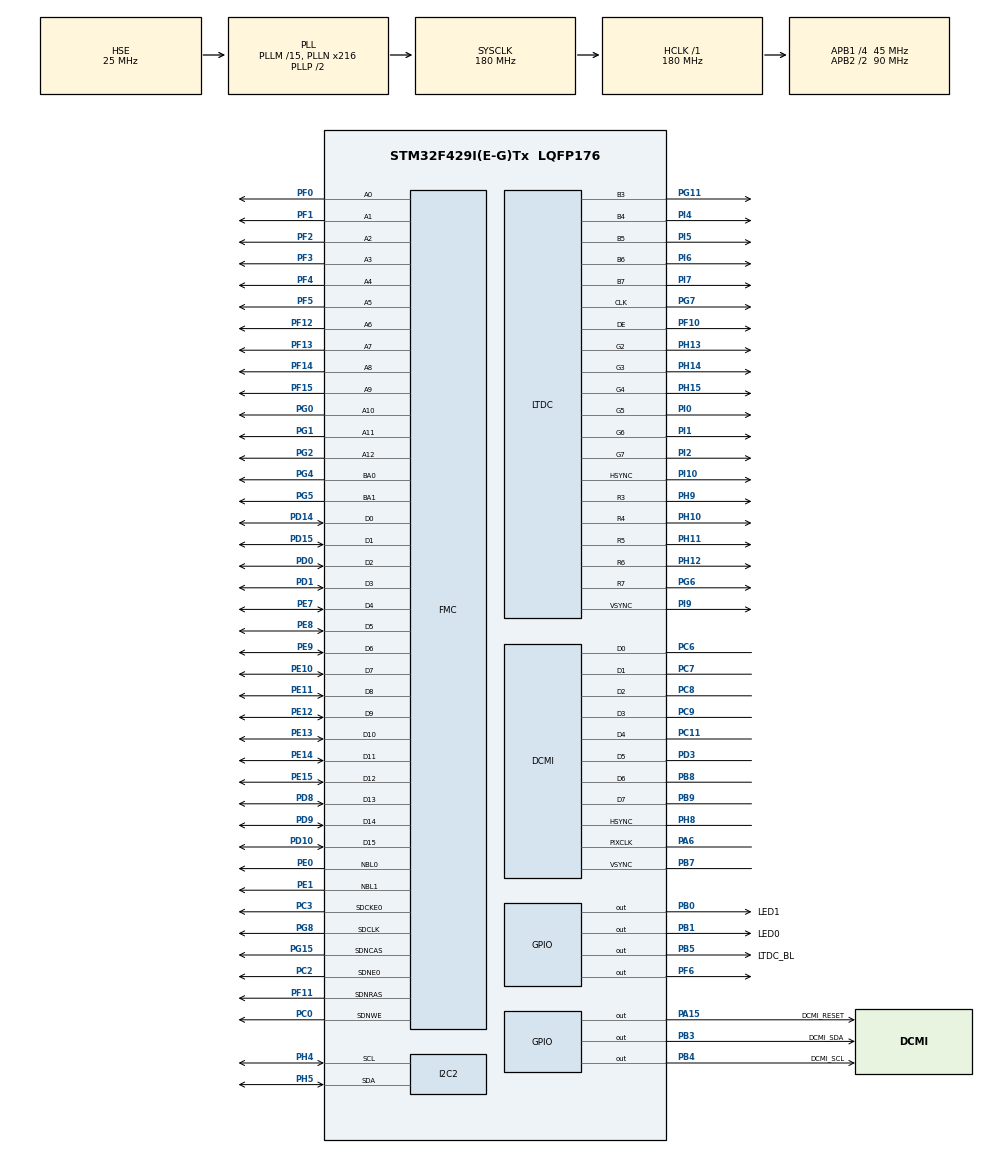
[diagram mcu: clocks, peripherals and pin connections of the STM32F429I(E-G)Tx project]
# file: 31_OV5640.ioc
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DCMI.PCKPolarity=DCMI_PCKPOLARITY_RISING
DMA2D.AlphaModeForeground=DMA2D_NO_MODIF_ALPHA
DMA2D.ColorMode=DMA2D_OUTPUT_RGB565
DMA2D.InputAlphaForeground=0
DMA2D.Mode=DMA2D_M2M
Dma.DCMI.0.Direction=DMA_PERIPH_TO_MEMORY
Dma.DCMI.0.FIFOMode=DMA_FIFOMODE_ENABLE
Dma.DCMI.0.FIFOThreshold=DMA_FIFO_THRESHOLD_HALFFULL
Dma.DCMI.0.Instance=DMA2_Stream1
Dma.DCMI.0.MemBurst=DMA_MBURST_SINGLE
Dma.DCMI.0.MemDataAlignment=DMA_MDATAALIGN_HALFWORD
Dma.DCMI.0.MemInc=DMA_MINC_ENABLE
Dma.DCMI.0.Mode=DMA_CIRCULAR
Dma.DCMI.0.PeriphBurst=DMA_PBURST_SINGLE
Dma.DCMI.0.PeriphDataAlignment=DMA_PDATAALIGN_WORD
Dma.DCMI.0.PeriphInc=DMA_PINC_DISABLE
Dma.DCMI.0.Priority=DMA_PRIORITY_HIGH
Dma.Request0=DCMI
FMC.CASLatency1=FMC_SDRAM_CAS_LATENCY_3
FMC.ColumnBitsNumber1=FMC_SDRAM_COLUMN_BITS_NUM_9
FMC.ExitSelfRefreshDelay1=7
FMC.LoadToActiveDelay1=2
FMC.RCDDelay1=2
FMC.RPDelay1=2
FMC.RPDelay2=2
FMC.ReadBurst1=FMC_SDRAM_RBURST_ENABLE
FMC.ReadBurst2=FMC_SDRAM_RBURST_ENABLE
FMC.ReadPipeDelay1=FMC_SDRAM_RPIPE_DELAY_1
FMC.ReadPipeDelay2=FMC_SDRAM_RPIPE_DELAY_1
FMC.RowCycleDelay1=6
FMC.RowCycleDelay2=6
FMC.SDClockPeriod1=FMC_SDRAM_CLOCK_PERIOD_2
FMC.SDClockPeriod2=FMC_SDRAM_CLOCK_PERIOD_2
FMC.SelfRefreshTime1=4
FMC.WriteRecoveryTime1=2
LTDC.ActiveH=600
LTDC.ActiveW=1024
LTDC.Alpha0_L1=255
LTDC.Alpha_L0=255
LTDC.Alpha_L1=0
LTDC.FBStartAdress_L0=0xC0000000
LTDC.FBStartAdress_L1=0xC0400000
LTDC.Green_L1=0
LTDC.HBP=140
LTDC.HFP=160
LTDC.HSync=20
LTDC.ImageHeight_L0=120
LTDC.ImageHeight_L1=120
LTDC.ImageWidth_L0=160
LTDC.ImageWidth_L1=160
LTDC.Layers=0
LTDC.PixelFormat_L0=LTDC_PIXEL_FORMAT_RGB565
LTDC.PixelFormat_L1=LTDC_PIXEL_FORMAT_RGB565
LTDC.VBP=20
LTDC.VFP=12
LTDC.VSync=3
LTDC.WindowX0_L1=200
LTDC.WindowX1_L0=159
LTDC.WindowX1_L1=359
LTDC.WindowY0_L1=200
LTDC.WindowY1_L0=119
LTDC.WindowY1_L1=319
Mcu.Family=STM32F4
Mcu.Name=STM32F429I(E-G)Tx
Mcu.Package=LQFP176
NVIC.DCMI_IRQn=true\:0\:1\:true\:false\:true\:true\:true
NVIC.DMA2_Stream1_IRQn=true\:0\:0\:false\:true\:true\:1\:false\:true
NVIC.PriorityGroup=NVIC_PRIORITYGROUP_2
PA13.Mode=Serial_Wire
PA13.Signal=SYS_JTMS-SWDIO
PA14.Mode=Serial_Wire
PA14.Signal=SYS_JTCK-SWCLK
PA15.GPIO_Label=DCMI_RESET
PA15.Signal=GPIO_Output
PA6.GPIO_PuPd=GPIO_PULLUP
PA6.GPIO_Speed=GPIO_SPEED_FREQ_VERY_HIGH
PA6.Mode=Slave_8_bits_External_Synchro
PA6.Signal=DCMI_PIXCLK
PB0.GPIO_Label=LED1
PB0.PinState=GPIO_PIN_SET
PB0.Signal=GPIO_Output
PB1.GPIO_Label=LED0
PB1.GPIO_PuPd=GPIO_PULLUP
PB1.PinState=GPIO_PIN_SET
PB1.Signal=GPIO_Output
PB3.GPIO_Label=DCMI_SDA
PB3.GPIO_ModeDefaultOutputPP=GPIO_MODE_OUTPUT_PP
PB3.GPIO_PuPd=GPIO_PULLUP
PB3.GPIO_Speed=GPIO_SPEED_FREQ_VERY_HIGH
PB3.Signal=GPIO_Output
PB4.GPIO_Label=DCMI_SCL
PB4.GPIO_ModeDefaultOutputPP=GPIO_MODE_OUTPUT_PP
PB4.GPIO_PuPd=GPIO_PULLUP
PB4.GPIO_Speed=GPIO_SPEED_FREQ_VERY_HIGH
PB4.Signal=GPIO_Output
PB5.GPIO_Label=LTDC_BL
PB5.Signal=GPIO_Output
PB7.GPIO_PuPd=GPIO_PULLUP
PB7.GPIO_Speed=GPIO_SPEED_FREQ_VERY_HIGH
PB7.Mode=Slave_8_bits_External_Synchro
PB7.Signal=DCMI_VSYNC
PB8.GPIO_PuPd=GPIO_PULLUP
PB8.GPIO_Speed=GPIO_SPEED_FREQ_VERY_HIGH
PB8.Mode=Slave_8_bits_External_Synchro
PB8.Signal=DCMI_D6
PB9.GPIO_PuPd=GPIO_PULLUP
PB9.GPIO_Speed=GPIO_SPEED_FREQ_VERY_HIGH
PB9.Mode=Slave_8_bits_External_Synchro
PB9.Signal=DCMI_D7
PC0.GPIO_Mode=GPIO_MODE_AF_PP
PC0.GPIO_PuPd=GPIO_PULLUP
PC0.GPIO_Speed_High_Default=GPIO_SPEED_FREQ_VERY_HIGH
PC0.Signal=FMC_SDNWE
PC11.GPIO_PuPd=GPIO_PULLUP
PC11.GPIO_Speed=GPIO_SPEED_FREQ_VERY_HIGH
PC11.Mode=Slave_8_bits_External_Synchro
PC11.Signal=DCMI_D4
PC14/OSC32_IN.Mode=LSE-External-Oscillator
PC14/OSC32_IN.Signal=RCC_OSC32_IN
PC15/OSC32_OUT.Mode=LSE-External-Oscillator
PC15/OSC32_OUT.Signal=RCC_OSC32_OUT
PC2.GPIO_Mode=GPIO_MODE_AF_PP
PC2.GPIO_PuPd=GPIO_PULLUP
PC2.GPIO_Speed_High_Default=GPIO_SPEED_FREQ_VERY_HIGH
PC2.Mode=SdramChipSelect1_1
PC2.Signal=FMC_SDNE0
PC3.GPIO_Mode=GPIO_MODE_AF_PP
PC3.GPIO_PuPd=GPIO_PULLUP
PC3.GPIO_Speed_High_Default=GPIO_SPEED_FREQ_VERY_HIGH
PC3.Mode=SdramChipSelect1_1
PC3.Signal=FMC_SDCKE0
PC6.GPIO_PuPd=GPIO_PULLUP
PC6.GPIO_Speed=GPIO_SPEED_FREQ_VERY_HIGH
PC6.Mode=Slave_8_bits_External_Synchro
PC6.Signal=DCMI_D0
PC7.GPIO_PuPd=GPIO_PULLUP
PC7.GPIO_Speed=GPIO_SPEED_FREQ_VERY_HIGH
PC7.Mode=Slave_8_bits_External_Synchro
PC7.Signal=DCMI_D1
PC8.GPIO_PuPd=GPIO_PULLUP
PC8.GPIO_Speed=GPIO_SPEED_FREQ_VERY_HIGH
PC8.Mode=Slave_8_bits_External_Synchro
PC8.Signal=DCMI_D2
PC9.GPIO_PuPd=GPIO_PULLUP
PC9.GPIO_Speed=GPIO_SPEED_FREQ_VERY_HIGH
PC9.Mode=Slave_8_bits_External_Synchro
PC9.Signal=DCMI_D3
PD0.GPIO_Mode=GPIO_MODE_AF_PP
PD0.GPIO_PuPd=GPIO_PULLUP
PD0.GPIO_Speed_High_Default=GPIO_SPEED_FREQ_VERY_HIGH
PD0.Signal=FMC_D2_DA2
PD1.GPIO_Mode=GPIO_MODE_AF_PP
PD1.GPIO_PuPd=GPIO_PULLUP
PD1.GPIO_Speed_High_Default=GPIO_SPEED_FREQ_VERY_HIGH
PD1.Signal=FMC_D3_DA3
PD10.GPIO_Mode=GPIO_MODE_AF_PP
PD10.GPIO_PuPd=GPIO_PULLUP
PD10.GPIO_Speed_High_Default=GPIO_SPEED_FREQ_VERY_HIGH
PD10.Signal=FMC_D15_DA15
PD14.GPIO_Mode=GPIO_MODE_AF_PP
PD14.GPIO_PuPd=GPIO_PULLUP
PD14.GPIO_Speed_High_Default=GPIO_SPEED_FREQ_VERY_HIGH
PD14.Signal=FMC_D0_DA0
PD15.GPIO_Mode=GPIO_MODE_AF_PP
PD15.GPIO_PuPd=GPIO_PULLUP
PD15.GPIO_Speed_High_Default=GPIO_SPEED_FREQ_VERY_HIGH
PD15.Signal=FMC_D1_DA1
PD3.GPIO_PuPd=GPIO_PULLUP
PD3.GPIO_Speed=GPIO_SPEED_FREQ_VERY_HIGH
PD3.Mode=Slave_8_bits_External_Synchro
PD3.Signal=DCMI_D5
PD8.GPIO_Mode=GPIO_MODE_AF_PP
PD8.GPIO_PuPd=GPIO_PULLUP
PD8.GPIO_Speed_High_Default=GPIO_SPEED_FREQ_VERY_HIGH
PD8.Signal=FMC_D13_DA13
PD9.GPIO_Mode=GPIO_MODE_AF_PP
PD9.GPIO_PuPd=GPIO_PULLUP
PD9.GPIO_Speed_High_Default=GPIO_SPEED_FREQ_VERY_HIGH
PD9.Signal=FMC_D14_DA14
PE0.GPIO_Mode=GPIO_MODE_AF_PP
PE0.GPIO_PuPd=GPIO_PULLUP
PE0.GPIO_Speed_High_Default=GPIO_SPEED_FREQ_VERY_HIGH
PE0.Signal=FMC_NBL0
PE1.GPIO_Mode=GPIO_MODE_AF_PP
PE1.GPIO_PuPd=GPIO_PULLUP
PE1.GPIO_Speed_High_Default=GPIO_SPEED_FREQ_VERY_HIGH
PE1.Signal=FMC_NBL1
PE10.GPIO_Mode=GPIO_MODE_AF_PP
PE10.GPIO_PuPd=GPIO_PULLUP
PE10.GPIO_Speed_High_Default=GPIO_SPEED_FREQ_VERY_HIGH
PE10.Signal=FMC_D7_DA7
PE11.GPIO_Mode=GPIO_MODE_AF_PP
PE11.GPIO_PuPd=GPIO_PULLUP
PE11.GPIO_Speed_High_Default=GPIO_SPEED_FREQ_VERY_HIGH
PE11.Signal=FMC_D8_DA8
PE12.GPIO_Mode=GPIO_MODE_AF_PP
PE12.GPIO_PuPd=GPIO_PULLUP
PE12.GPIO_Speed_High_Default=GPIO_SPEED_FREQ_VERY_HIGH
PE12.Signal=FMC_D9_DA9
PE13.GPIO_Mode=GPIO_MODE_AF_PP
PE13.GPIO_PuPd=GPIO_PULLUP
PE13.GPIO_Speed_High_Default=GPIO_SPEED_FREQ_VERY_HIGH
PE13.Signal=FMC_D10_DA10
PE14.GPIO_Mode=GPIO_MODE_AF_PP
PE14.GPIO_PuPd=GPIO_PULLUP
PE14.GPIO_Speed_High_Default=GPIO_SPEED_FREQ_VERY_HIGH
PE14.Signal=FMC_D11_DA11
PE15.GPIO_Mode=GPIO_MODE_AF_PP
PE15.GPIO_PuPd=GPIO_PULLUP
PE15.GPIO_Speed_High_Default=GPIO_SPEED_FREQ_VERY_HIGH
PE15.Signal=FMC_D12_DA12
PE7.GPIO_Mode=GPIO_MODE_AF_PP
PE7.GPIO_PuPd=GPIO_PULLUP
PE7.GPIO_Speed_High_Default=GPIO_SPEED_FREQ_VERY_HIGH
PE7.Signal=FMC_D4_DA4
PE8.GPIO_Mode=GPIO_MODE_AF_PP
PE8.GPIO_PuPd=GPIO_PULLUP
PE8.GPIO_Speed_High_Default=GPIO_SPEED_FREQ_VERY_HIGH
PE8.Signal=FMC_D5_DA5
PE9.GPIO_Mode=GPIO_MODE_AF_PP
PE9.GPIO_PuPd=GPIO_PULLUP
PE9.GPIO_Speed_High_Default=GPIO_SPEED_FREQ_VERY_HIGH
PE9.Signal=FMC_D6_DA6
PF0.GPIO_Mode=GPIO_MODE_AF_PP
PF0.GPIO_PuPd=GPIO_PULLUP
PF0.GPIO_Speed_High_Default=GPIO_SPEED_FREQ_VERY_HIGH
PF0.Signal=FMC_A0
PF1.GPIO_Mode=GPIO_MODE_AF_PP
PF1.GPIO_PuPd=GPIO_PULLUP
PF1.GPIO_Speed_High_Default=GPIO_SPEED_FREQ_VERY_HIGH
PF1.Signal=FMC_A1
PF10.GPIO_Speed=GPIO_SPEED_FREQ_VERY_HIGH
PF10.Mode=RGB565
PF10.Signal=LTDC_DE
PF11.GPIO_Mode=GPIO_MODE_AF_PP
PF11.GPIO_PuPd=GPIO_PULLUP
PF11.GPIO_Speed_High_Default=GPIO_SPEED_FREQ_VERY_HIGH
PF11.Signal=FMC_SDNRAS
PF12.GPIO_Mode=GPIO_MODE_AF_PP
PF12.GPIO_PuPd=GPIO_PULLUP
PF12.GPIO_Speed_High_Default=GPIO_SPEED_FREQ_VERY_HIGH
PF12.Signal=FMC_A6
PF13.GPIO_Mode=GPIO_MODE_AF_PP
PF13.GPIO_PuPd=GPIO_PULLUP
PF13.GPIO_Speed_High_Default=GPIO_SPEED_FREQ_VERY_HIGH
PF13.Signal=FMC_A7
PF14.GPIO_Mode=GPIO_MODE_AF_PP
PF14.GPIO_PuPd=GPIO_PULLUP
PF14.GPIO_Speed_High_Default=GPIO_SPEED_FREQ_VERY_HIGH
PF14.Signal=FMC_A8
PF15.GPIO_Mode=GPIO_MODE_AF_PP
PF15.GPIO_PuPd=GPIO_PULLUP
PF15.GPIO_Speed_High_Default=GPIO_SPEED_FREQ_VERY_HIGH
PF15.Signal=FMC_A9
PF2.GPIO_Mode=GPIO_MODE_AF_PP
PF2.GPIO_PuPd=GPIO_PULLUP
PF2.GPIO_Speed_High_Default=GPIO_SPEED_FREQ_VERY_HIGH
PF2.Signal=FMC_A2
PF3.GPIO_Mode=GPIO_MODE_AF_PP
PF3.GPIO_PuPd=GPIO_PULLUP
PF3.GPIO_Speed_High_Default=GPIO_SPEED_FREQ_VERY_HIGH
PF3.Signal=FMC_A3
PF4.GPIO_Mode=GPIO_MODE_AF_PP
PF4.GPIO_PuPd=GPIO_PULLUP
PF4.GPIO_Speed_High_Default=GPIO_SPEED_FREQ_VERY_HIGH
PF4.Signal=FMC_A4
PF5.GPIO_Mode=GPIO_MODE_AF_PP
PF5.GPIO_PuPd=GPIO_PULLUP
PF5.GPIO_Speed_High_Default=GPIO_SPEED_FREQ_VERY_HIGH
PF5.Signal=FMC_A5
PF6.GPIO_Speed=GPIO_SPEED_FREQ_VERY_HIGH
PF6.Signal=GPIO_Output
PG0.GPIO_Mode=GPIO_MODE_AF_PP
PG0.GPIO_PuPd=GPIO_PULLUP
PG0.GPIO_Speed_High_Default=GPIO_SPEED_FREQ_VERY_HIGH
PG0.Signal=FMC_A10
PG1.GPIO_Mode=GPIO_MODE_AF_PP
PG1.GPIO_PuPd=GPIO_PULLUP
PG1.GPIO_Speed_High_Default=GPIO_SPEED_FREQ_VERY_HIGH
PG1.Signal=FMC_A11
PG11.GPIO_Speed=GPIO_SPEED_FREQ_VERY_HIGH
PG11.Mode=RGB565
PG11.Signal=LTDC_B3
PG15.GPIO_Mode=GPIO_MODE_AF_PP
PG15.GPIO_PuPd=GPIO_PULLUP
PG15.GPIO_Speed_High_Default=GPIO_SPEED_FREQ_VERY_HIGH
PG15.Signal=FMC_SDNCAS
PG2.GPIO_Mode=GPIO_MODE_AF_PP
PG2.GPIO_PuPd=GPIO_PULLUP
PG2.GPIO_Speed_High_Default=GPIO_SPEED_FREQ_VERY_HIGH
PG2.Signal=FMC_A12
PG4.GPIO_Mode=GPIO_MODE_AF_PP
PG4.GPIO_PuPd=GPIO_PULLUP
PG4.GPIO_Speed_High_Default=GPIO_SPEED_FREQ_VERY_HIGH
PG4.Signal=FMC_A14_BA0
PG5.GPIO_Mode=GPIO_MODE_AF_PP
PG5.GPIO_PuPd=GPIO_PULLUP
PG5.GPIO_Speed_High_Default=GPIO_SPEED_FREQ_VERY_HIGH
PG5.Signal=FMC_A15_BA1
PG6.GPIO_Speed=GPIO_SPEED_FREQ_VERY_HIGH
PG6.Mode=RGB565
PG6.Signal=LTDC_R7
PG7.GPIO_Speed=GPIO_SPEED_FREQ_VERY_HIGH
PG7.Mode=RGB565
PG7.Signal=LTDC_CLK
PG8.GPIO_Mode=GPIO_MODE_AF_PP
PG8.GPIO_PuPd=GPIO_PULLUP
PG8.GPIO_Speed_High_Default=GPIO_SPEED_FREQ_VERY_HIGH
PG8.Signal=FMC_SDCLK
PH0/OSC_IN.Mode=HSE-External-Oscillator
PH0/OSC_IN.Signal=RCC_OSC_IN
PH1/OSC_OUT.Mode=HSE-External-Oscillator
PH1/OSC_OUT.Signal=RCC_OSC_OUT
PH10.GPIO_Speed=GPIO_SPEED_FREQ_VERY_HIGH
PH10.Mode=RGB565
PH10.Signal=LTDC_R4
PH11.GPIO_Speed=GPIO_SPEED_FREQ_VERY_HIGH
PH11.Mode=RGB565
PH11.Signal=LTDC_R5
PH12.GPIO_Speed=GPIO_SPEED_FREQ_VERY_HIGH
PH12.Mode=RGB565
PH12.Signal=LTDC_R6
PH13.GPIO_Speed=GPIO_SPEED_FREQ_VERY_HIGH
PH13.Mode=RGB565
PH13.Signal=LTDC_G2
PH14.GPIO_Speed=GPIO_SPEED_FREQ_VERY_HIGH
PH14.Mode=RGB565
PH14.Signal=LTDC_G3
PH15.GPIO_Speed=GPIO_SPEED_FREQ_VERY_HIGH
PH15.Mode=RGB565
PH15.Signal=LTDC_G4
PH4.Mode=I2C
PH4.Signal=I2C2_SCL
PH5.Mode=I2C
PH5.Signal=I2C2_SDA
PH8.GPIO_PuPd=GPIO_PULLUP
PH8.GPIO_Speed=GPIO_SPEED_FREQ_VERY_HIGH
PH8.Mode=Slave_8_bits_External_Synchro
PH8.Signal=DCMI_HSYNC
PH9.GPIO_Speed=GPIO_SPEED_FREQ_VERY_HIGH
PH9.Mode=RGB565
PH9.Signal=LTDC_R3
PI0.GPIO_Speed=GPIO_SPEED_FREQ_VERY_HIGH
PI0.Mode=RGB565
PI0.Signal=LTDC_G5
PI1.GPIO_Speed=GPIO_SPEED_FREQ_VERY_HIGH
PI1.Mode=RGB565
PI1.Signal=LTDC_G6
PI10.GPIO_Speed=GPIO_SPEED_FREQ_VERY_HIGH
PI10.Mode=RGB565
PI10.Signal=LTDC_HSYNC
PI2.GPIO_Speed=GPIO_SPEED_FREQ_VERY_HIGH
PI2.Mode=RGB565
PI2.Signal=LTDC_G7
PI4.GPIO_Speed=GPIO_SPEED_FREQ_VERY_HIGH
PI4.Mode=RGB565
PI4.Signal=LTDC_B4
PI5.GPIO_Speed=GPIO_SPEED_FREQ_VERY_HIGH
PI5.Mode=RGB565
PI5.Signal=LTDC_B5
PI6.GPIO_Speed=GPIO_SPEED_FREQ_VERY_HIGH
PI6.Mode=RGB565
PI6.Signal=LTDC_B6
PI7.GPIO_Speed=GPIO_SPEED_FREQ_VERY_HIGH
PI7.Mode=RGB565
PI7.Signal=LTDC_B7
PI9.GPIO_Speed=GPIO_SPEED_FREQ_VERY_HIGH
PI9.Mode=RGB565
PI9.Signal=LTDC_VSYNC
ProjectManager.HeapSize=0x200
ProjectManager.StackSize=0x400
ProjectManager.TargetToolchain=STM32CubeIDE
RCC.48MHZClocksFreq_Value=90000000
RCC.AHBFreq_Value=180000000
RCC.APB1CLKDivider=RCC_HCLK_DIV4
RCC.APB1Freq_Value=45000000
RCC.APB1TimFreq_Value=90000000
RCC.APB2CLKDivider=RCC_HCLK_DIV2
RCC.APB2Freq_Value=90000000
RCC.APB2TimFreq_Value=180000000
RCC.CortexFreq_Value=180000000
RCC.HCLKFreq_Value=180000000
RCC.HSE_VALUE=25000000
RCC.HSI_VALUE=16000000
RCC.PLLM=15
RCC.PLLN=216
RCC.PLLSAIN=168
RCC.PLLSAIR=5
RCC.PLLSourceVirtual=RCC_PLLSOURCE_HSE
RCC.SYSCLKFreq_VALUE=180000000
RCC.SYSCLKSource=RCC_SYSCLKSOURCE_PLLCLK
RCC.VCOOutputFreq_Value=360000000
SH.FMC_A0.0=FMC_A0,13b-sda1
SH.FMC_A1.0=FMC_A1,13b-sda1
SH.FMC_A10.0=FMC_A10,13b-sda1
SH.FMC_A11.0=FMC_A11,13b-sda1
SH.FMC_A12.0=FMC_A12,13b-sda1
SH.FMC_A14_BA0.0=FMC_BA0,FourSdramBanks1
SH.FMC_A15_BA1.0=FMC_BA1,FourSdramBanks1
SH.FMC_A2.0=FMC_A2,13b-sda1
SH.FMC_A3.0=FMC_A3,13b-sda1
SH.FMC_A4.0=FMC_A4,13b-sda1
SH.FMC_A5.0=FMC_A5,13b-sda1
SH.FMC_A6.0=FMC_A6,13b-sda1
SH.FMC_A7.0=FMC_A7,13b-sda1
SH.FMC_A8.0=FMC_A8,13b-sda1
SH.FMC_A9.0=FMC_A9,13b-sda1
SH.FMC_D0_DA0.0=FMC_D0,sd-16b-d1
SH.FMC_D10_DA10.0=FMC_D10,sd-16b-d1
SH.FMC_D11_DA11.0=FMC_D11,sd-16b-d1
SH.FMC_D12_DA12.0=FMC_D12,sd-16b-d1
SH.FMC_D13_DA13.0=FMC_D13,sd-16b-d1
SH.FMC_D14_DA14.0=FMC_D14,sd-16b-d1
SH.FMC_D15_DA15.0=FMC_D15,sd-16b-d1
SH.FMC_D1_DA1.0=FMC_D1,sd-16b-d1
SH.FMC_D2_DA2.0=FMC_D2,sd-16b-d1
SH.FMC_D3_DA3.0=FMC_D3,sd-16b-d1
SH.FMC_D4_DA4.0=FMC_D4,sd-16b-d1
SH.FMC_D5_DA5.0=FMC_D5,sd-16b-d1
SH.FMC_D6_DA6.0=FMC_D6,sd-16b-d1
SH.FMC_D7_DA7.0=FMC_D7,sd-16b-d1
SH.FMC_D8_DA8.0=FMC_D8,sd-16b-d1
SH.FMC_D9_DA9.0=FMC_D9,sd-16b-d1
SH.FMC_NBL0.0=FMC_NBL0,Sd2ByteEnable1
SH.FMC_NBL1.0=FMC_NBL1,Sd2ByteEnable1
SH.FMC_SDCLK.0=FMC_SDCLK,13b-sda1
SH.FMC_SDNCAS.0=FMC_SDNCAS,13b-sda1
SH.FMC_SDNRAS.0=FMC_SDNRAS,13b-sda1
SH.FMC_SDNWE.0=FMC_SDNWE,13b-sda1
VP_DMA2D_VS_DMA2D.Mode=DMA2D_Activate
board=custom

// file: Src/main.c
/* USER CODE BEGIN Header */
/**
 ******************************************************************************
 * @file           : main.c
 * @brief          : Main program body
 ******************************************************************************
 * @attention
 *
 * <h2><center>&copy; Copyright (c) 2019 STMicroelectronics.
 * All rights reserved.</center></h2>
 *
 * This software component is licensed by ST under BSD 3-Clause license,
 * the "License"; You may not use this file except in compliance with the
 * License. You may obtain a copy of the License at:
 *                        opensource.org/licenses/BSD-3-Clause
 *
 ******************************************************************************
 */
/* USER CODE END Header */

#include "main.h"
#include "dcmi.h"
#include "dma.h"
#include "dma2d.h"
#include "i2c.h"
#include "ltdc.h"
#include "gpio.h"
#include "fmc.h"

/* USER CODE BEGIN Includes */
#include "LTDC_LCD.h"
#include "sdRAM.h"
#include "OV5640.h"
//#include "RGB565_240x130_1.h"
//#include "RGB565_320x240.h"
//#include"test_pic3.h"
/* USER CODE END Includes */

/* USER CODE BEGIN PD */
#define SDRAM_BANK_ADDR     ((uint32_t)0XC0000000)
#define jpeg_buf_size   30*1024*1024		//定义JPEG数据缓存jpeg_buf的大�???????????????????????(1*4M字节)
#define jpeg_line_size	2*1024			//定义DMA接收数据�???????????????????????,�???????????????????????行数据的�???????????????????????大�??

typedef int32_t s32;
typedef int16_t s16;
typedef int8_t s8;

typedef const int32_t sc32;
typedef const int16_t sc16;
typedef const int8_t sc8;

typedef __IO int32_t vs32;
typedef __IO int16_t vs16;
typedef __IO int8_t vs8;

typedef __I int32_t vsc32;
typedef __I int16_t vsc16;
typedef __I int8_t vsc8;

typedef uint32_t u32;
typedef uint16_t u16;
typedef uint8_t u8;

typedef const uint32_t uc32;
typedef const uint16_t uc16;
typedef const uint8_t uc8;

typedef __IO uint32_t vu32;
typedef __IO uint16_t vu16;
typedef __IO uint8_t vu8;

typedef __I uint32_t vuc32;
typedef __I uint16_t vuc16;
typedef __I uint8_t vuc8;

/* USER CODE END PD */

/* USER CODE BEGIN PV */
uint32_t buffer0[1200 * 800] __attribute__((section(".ExtRAMData"))); // 1024 * 1024 /4    //1MB / 4
uint32_t buffer1[1200 * 800] __attribute__((section(".ExtRAMData1"))); // 1024 * 1024 /4    //1MB / 4
//uint32_t dcmi_line_buf[2][jpeg_line_size];	//RGB屏时,摄像头采用一行一行读�???????????????????????,定义行缓�???????????????????????

//uint32_t line_buf[1024 * 4];

uint32_t pic_buf[2][160 * 120];

extern DCMI_HandleTypeDef hdcmi;
extern DMA_HandleTypeDef hdma_dcmi;

typedef struct
{
    vu16 LCD_REG;
    vu16 LCD_RAM;
} LCD_TypeDef;

#define LCD_BASE        ((u32)(0x60000000 | 0x0007FFFE))
#define LCD             ((LCD_TypeDef *) LCD_BASE)

u16 curline = 0;							//摄像头输出数�????????????????????,当前行编�????????????????????
u16 yoffset = 0;							//y方向的偏移量

volatile uint32_t temp2 = 0;
volatile uint32_t line_callback = 0;
volatile uint32_t error_callback = 0;
volatile uint32_t frame_callback = 0;
volatile uint32_t vsync_callback = 0;
volatile uint32_t dma_callback = 0;

volatile uint32_t m1 = 0;
volatile uint32_t m2 = 0;

volatile uint8_t flag = 0;
volatile uint16_t rx_times = 1;
volatile uint16_t line_rx_times = 0;

uint32_t vsync_call = 0;
uint32_t hsync_call = 0;
uint32_t line_call = 0;
uint32_t temp_check = 0;

uint32_t t1, t2, t3;
uint32_t i, j;

int a = 320;
int b = 240;
int c = 120;

/* USER CODE END PV */

void SystemClock_Config(void);
static void MX_NVIC_Init(void);

/* USER CODE BEGIN 0 */

void DCMI_STOP(DCMI_HandleTypeDef*hdcmi)
{
    HAL_StatusTypeDef status = HAL_OK;

    /* Process locked */
    __HAL_LOCK(hdcmi);

    /* Lock the DCMI peripheral state */
    hdcmi->State = HAL_DCMI_STATE_BUSY;

    /* Disable Capture */
    hdcmi->Instance->CR &= ~(DCMI_CR_CAPTURE);

    while((hdcmi->Instance->CR & DCMI_CR_CAPTURE) != 0U);

    /* Disable the DCMI */
    __HAL_DCMI_DISABLE(hdcmi);

    /* Disable the DMA */
    HAL_DMA_Abort(hdcmi->DMA_Handle);

    /* Update error code */
    hdcmi->ErrorCode |= HAL_DCMI_ERROR_NONE;

    /* Change DCMI state */
    hdcmi->State = HAL_DCMI_STATE_READY;

    /* Process Unlocked */
    __HAL_UNLOCK(hdcmi);

}

void HAL_DCMI_LineEventCallback (DCMI_HandleTypeDef*hdcmi)
{
    HAL_GPIO_TogglePin (LED1_GPIO_Port, LED1_Pin);
    line_rx_times++;
    if (line_rx_times == b)
    {
	DCMI_STOP (hdcmi);
	if (flag)
	{
	    hdma_dcmi.Instance->M0AR = &buffer1;
	    HAL_LTDC_SetAddress (&hltdc, &buffer0, 0);
	    HAL_DCMI_Start_DMA (hdcmi, DCMI_MODE_CONTINUOUS, &buffer1, a * c);

	    flag = 0;
	}
	else
	{
	    hdma_dcmi.Instance->M0AR = &buffer0;
	    HAL_LTDC_SetAddress (&hltdc, &buffer1, 0);
	    HAL_DCMI_Start_DMA (hdcmi, DCMI_MODE_CONTINUOUS, &buffer0, a * c);

	    flag = 1;
	}
	line_rx_times = 0;
    }

}
void HAL_DCMI_VsyncEventCallback (DCMI_HandleTypeDef*hdcmi)
{
    //m1++;
//    HAL_DMA2D_Abort (&hdma2d);
//    if ((hdcmi->DMA_Handle->Instance->CR & DMA_SxCR_CT) == 0U)
//    {
//	m1++;
//	HAL_DMA2D_Start (&hdma2d, (uint32_t) &pic_buf[1], (uint32_t) &aMemory0, 160, 120);
//    }
//    else
//    {
//	m2++;
//	HAL_DMA2D_Start (&hdma2d, (uint32_t) &pic_buf[0], (uint32_t) &aMemory0, 160, 120);
//    }
}

void dcmi_rx_callback ()
{
    //HAL_DCMI_Stop (&hdcmi);

    rx_times++;
    //HAL_GPIO_TogglePin (LED1_GPIO_Port, LED1_Pin);
//    if (flag)
//    {
//	hdma_dcmi.Instance->M0AR = &buffer1 + (rx_times - 1) * a * b / 2;
//	HAL_DCMI_Start_DMA (&hdcmi, DCMI_MODE_CONTINUOUS, &buffer1 + (rx_times - 1) * a * b / 2, a * b / 2);
//	if (rx_times == 1)
//	{
//	    HAL_LTDC_SetAddress (&hltdc, &buffer0, 0);
//	}
//	else if (rx_times == 2)
//	{
//	    rx_times = 0;
//	    flag = 0;
//	}
//    }
//    else
//    {
//	hdma_dcmi.Instance->M0AR = &buffer0 + (rx_times - 1) * a * b / 2;
//	HAL_DCMI_Start_DMA (&hdcmi, DCMI_MODE_CONTINUOUS, &buffer0 + (rx_times - 1) * a * b / 2, a * b / 2);
//	if (rx_times == 1)
//	{
//	    HAL_LTDC_SetAddress (&hltdc, &buffer1, 0);
//	}
//	else if (rx_times == 2)
//	{
//	    rx_times = 0;
//	    flag = 1;
//	}
//    }

//    if (flag)
//    {
//	//hdma_dcmi.Instance->M0AR = &buffer1;
//	HAL_LTDC_SetAddress (&hltdc, &buffer0, 0);
//	HAL_DCMI_Start_DMA (&hdcmi, DCMI_MODE_CONTINUOUS, &buffer1, a * b);
////	HAL_GPIO_WritePin(LED1_GPIO_Port, LED1_Pin, flag);
//	flag = 0;
//    }
//    else
//    {
//	//hdma_dcmi.Instance->M0AR = &buffer0;
//	HAL_LTDC_SetAddress (&hltdc, &buffer1, 0);
//	HAL_DCMI_Start_DMA (&hdcmi, DCMI_MODE_CONTINUOUS, &buffer0, a * b);
////	HAL_GPIO_WritePin(LED1_GPIO_Port, LED1_Pin, flag);
//	flag = 1;
//    }
}

/* USER CODE END 0 */

int main(void)
{

  /* MCU Configuration--------------------------------------------------------*/

  /* Reset of all peripherals, Initializes the Flash interface and the Systick. */
  HAL_Init();

  /* Configure the system clock */
  SystemClock_Config();

  /* Initialize all configured peripherals */
  MX_GPIO_Init();
  MX_DMA_Init();
  MX_DCMI_Init();
  MX_FMC_Init();
  MX_LTDC_Init();
  MX_DMA2D_Init();
  MX_I2C2_Init();

  /* Initialize interrupts */
  MX_NVIC_Init();
  /* USER CODE BEGIN 2 */

//LCD_Init ();
    SDRAM_Init ();

    HAL_GPIO_WritePin (LTDC_BL_GPIO_Port, LTDC_BL_Pin, 1);

//    HAL_LTDC_SetWindowSize (&hltdc, 1024, 600, 0);
//
    for (int i = 0; i < 1024 * 600; i++)
    {
	buffer0[i] = 0xFF00FF;
    }
    for (int j = 0; j < 1024 * 600; j++)
    {
	buffer1[j] = 0xFF00FF;
    }

    OV5640_Init ();

    OV5640_RGB565_Mode ();
    //OV5640_Focus_Init ();
    OV5640_Light_Mode (0);	//自动模式
    OV5640_Color_Saturation (3);	//色彩饱和
    OV5640_Brightness (4);	//亮度0
    OV5640_Contrast (3);		//对比
    OV5640_Sharpness (33);	//自动锐度
    //OV5640_Focus_Constant ();	//启动持续对焦

    //app_160x120_camera_rolling ();

    HAL_LTDC_SetWindowSize (&hltdc, a, b, 0);
    OV5640_OutSize_Set (0, 0, a, b);
    HAL_LTDC_SetAddress (&hltdc, &buffer0, 0);
    HAL_DCMI_Start_DMA (&hdcmi, DCMI_MODE_CONTINUOUS, &buffer1, a * c);
    while (1)
    {
//	HAL_Delay (1000);
//	HAL_LTDC_SetAddress (&hltdc, &buffer1, 0);
//	HAL_LTDC_Reload(&hltdc, LTDC_RELOAD_IMMEDIATE);
//	HAL_Delay (1000);
//	HAL_LTDC_SetAddress (&hltdc, &buffer0, 0);
//	HAL_LTDC_Reload(&hltdc, LTDC_RELOAD_IMMEDIATE);
    }

  /* USER CODE END 2 */

  /* Infinite loop */
    while (1)
    {

    }
}

void SystemClock_Config(void)
{
  RCC_OscInitTypeDef RCC_OscInitStruct = {0};
  RCC_ClkInitTypeDef RCC_ClkInitStruct = {0};
  RCC_PeriphCLKInitTypeDef PeriphClkInitStruct = {0};

  /** Configure the main internal regulator output voltage
  */
  __HAL_RCC_PWR_CLK_ENABLE();
  __HAL_PWR_VOLTAGESCALING_CONFIG(PWR_REGULATOR_VOLTAGE_SCALE1);
  /** Initializes the CPU, AHB and APB busses clocks
  */
  RCC_OscInitStruct.OscillatorType = RCC_OSCILLATORTYPE_HSE;
  RCC_OscInitStruct.HSEState = RCC_HSE_ON;
  RCC_OscInitStruct.PLL.PLLState = RCC_PLL_ON;
  RCC_OscInitStruct.PLL.PLLSource = RCC_PLLSOURCE_HSE;
  RCC_OscInitStruct.PLL.PLLM = 15;
  RCC_OscInitStruct.PLL.PLLN = 216;
  RCC_OscInitStruct.PLL.PLLP = RCC_PLLP_DIV2;
  RCC_OscInitStruct.PLL.PLLQ = 4;
  if (HAL_RCC_OscConfig(&RCC_OscInitStruct) != HAL_OK)
  {
    Error_Handler();
  }
  /** Activate the Over-Drive mode
  */
  if (HAL_PWREx_EnableOverDrive() != HAL_OK)
  {
    Error_Handler();
  }
  /** Initializes the CPU, AHB and APB busses clocks
  */
  RCC_ClkInitStruct.ClockType = RCC_CLOCKTYPE_HCLK|RCC_CLOCKTYPE_SYSCLK
                              |RCC_CLOCKTYPE_PCLK1|RCC_CLOCKTYPE_PCLK2;
  RCC_ClkInitStruct.SYSCLKSource = RCC_SYSCLKSOURCE_PLLCLK;
  RCC_ClkInitStruct.AHBCLKDivider = RCC_SYSCLK_DIV1;
  RCC_ClkInitStruct.APB1CLKDivider = RCC_HCLK_DIV4;
  RCC_ClkInitStruct.APB2CLKDivider = RCC_HCLK_DIV2;

  if (HAL_RCC_ClockConfig(&RCC_ClkInitStruct, FLASH_LATENCY_5) != HAL_OK)
  {
    Error_Handler();
  }
  PeriphClkInitStruct.PeriphClockSelection = RCC_PERIPHCLK_LTDC;
  PeriphClkInitStruct.PLLSAI.PLLSAIN = 168;
  PeriphClkInitStruct.PLLSAI.PLLSAIR = 5;
  PeriphClkInitStruct.PLLSAIDivR = RCC_PLLSAIDIVR_2;
  if (HAL_RCCEx_PeriphCLKConfig(&PeriphClkInitStruct) != HAL_OK)
  {
    Error_Handler();
  }
}

/**
  * @brief NVIC Configuration.
  * @retval None
  */
static void MX_NVIC_Init(void)
{
  /* DMA2_Stream1_IRQn interrupt configuration */
  HAL_NVIC_SetPriority(DMA2_Stream1_IRQn, 0, 0);
  HAL_NVIC_EnableIRQ(DMA2_Stream1_IRQn);
}

/* USER CODE BEGIN 4 */

//DCMI中断服务函数
//void DCMI_IRQHandler (void)
//{
//    HAL_DCMI_IRQHandler (&hdma_dcmi);
//}
//DMA2数据�???????????????????????1中断服务函数
//void DMA2_Stream1_IRQHandler (void)
//{
//    if (__HAL_DMA_GET_FLAG(&hdma_dcmi,DMA_FLAG_TCIF1_5) != RESET)          //DMA传输完成
//    {
//	__HAL_DMA_CLEAR_FLAG(&hdma_dcmi, DMA_FLAG_TCIF1_5);          //清除DMA传输完成中断标志�???????????????????????
//	dcmi_rx_callback ();	//执行摄像头接收回调函�???????????????????????,读取数据等操作在这里面处�???????????????????????
//    }
//}
void app_160x120_camera_rolling ()
{

    //HAL_LTDC_SetWindowSize (&hltdc, 160, 120, 0);

    OV5640_OutSize_Set (4, 0, 160, 120);

    __HAL_LOCK(&hdcmi); // @suppress("Unused return value")
    hdcmi.State = HAL_DCMI_STATE_BUSY;
    __HAL_DCMI_ENABLE(&hdcmi);
    hdcmi.Instance->CR &= ~(DCMI_CR_CM);
    hdcmi.Instance->CR |= (uint32_t) (DCMI_MODE_CONTINUOUS);
    HAL_DMAEx_MultiBufferStart (hdcmi.DMA_Handle, (uint32_t) &hdcmi.Instance->DR, &buffer0, &buffer1, 160 * 120);		//

    hdcmi.Instance->CR |= DCMI_CR_CAPTURE;
    __HAL_UNLOCK(&hdcmi);
    while (1);
//    int index = 0;
//    while (1)
//    {
//	for (index = 0; index < 400; index++)
//	{
//	    HAL_LTDC_SetWindowPosition_NoReload (&hltdc, index * 2, index, 0);
//	    HAL_LTDC_Reload (&hltdc, LTDC_RELOAD_VERTICAL_BLANKING);
//	    HAL_Delay (5);
//	}
//	HAL_Delay (500);
//	for (index = 0; index < 400; index++)
//	{
//	    HAL_LTDC_SetWindowPosition_NoReload (&hltdc, 800 - index * 2, 400 - index, 0);
//	    HAL_LTDC_Reload (&hltdc, LTDC_RELOAD_VERTICAL_BLANKING);
//	    HAL_Delay (5);
//	}
//	HAL_Delay (500);
//    }
}

void app_large_image ()
{
    HAL_LTDC_SetWindowSize (&hltdc, 320, 240, 0);
    OV5640_OutSize_Set (4, 0, 320, 240);
    __HAL_LOCK(&hdcmi); // @suppress("Unused return value")
    hdcmi.State = HAL_DCMI_STATE_BUSY;
    __HAL_DCMI_ENABLE(&hdcmi);
    hdcmi.Instance->CR &= ~(DCMI_CR_CM);
    hdcmi.Instance->CR |= (uint32_t) (DCMI_MODE_CONTINUOUS);
    HAL_DMAEx_MultiBufferStart (hdcmi.DMA_Handle, (uint32_t) &hdcmi.Instance->DR, &buffer0[0], &buffer0[1], 160 * 120);		//
    hdcmi.Instance->CR |= DCMI_CR_CAPTURE;
    __HAL_UNLOCK(&hdcmi);

}
/* USER CODE END 4 */

void Error_Handler(void)
{
  /* USER CODE BEGIN Error_Handler_Debug */
    /* User can add his own implementation to report the HAL error return state */
    HAL_GPIO_WritePin (LED0_GPIO_Port, LED0_Pin, 0);
  /* USER CODE END Error_Handler_Debug */
}

/************************ (C) COPYRIGHT STMicroelectronics *****END OF FILE****/
